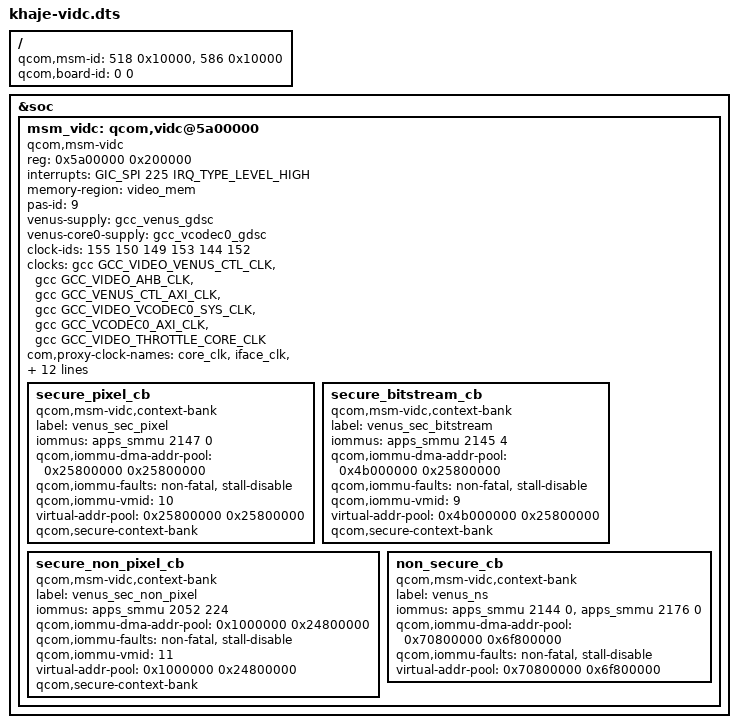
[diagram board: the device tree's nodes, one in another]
// SPDX-License-Identifier: GPL-2.0-only
/*
 * khaje video (msm_vidc) base overlay
 *
 * Reconstructed from the stock Redmi Note 13 4G (sapphire) vendor_boot DTB
 * (HyperOS OS2.0.215.0.VNHEUXM): the Qualcomm "video-devicetree" techpack
 * devicetree is not published, so this overlay was rebuilt from the nodes
 * and properties it contributes to the merged khaje base DTB.  It is applied
 * onto qcom/khaje.dtb with fdtoverlay, as kernel_platform merge_dtbs.py does.
 */

/dts-v1/;
/plugin/;

#include <dt-bindings/clock/qcom,gcc-khaje.h>
#include <dt-bindings/interconnect/qcom,bengal.h>
#include <dt-bindings/interrupt-controller/arm-gic.h>

/ {
	qcom,msm-id = <518 0x10000>, <586 0x10000>;
	qcom,board-id = <0 0>;
};

&soc {
	msm_vidc: qcom,vidc@5a00000 {
		compatible = "qcom,msm-vidc", "qcom,msm-vidc-khaje", "qcom,msm-vidc-ar50lt";
		status = "okay";
		reg = <0x5a00000 0x200000>;
		interrupts = <GIC_SPI 225 IRQ_TYPE_LEVEL_HIGH>;
		memory-region = <&video_mem>;
		pas-id = <9>;
		#address-cells = <1>;
		#size-cells = <1>;
		venus-supply = <&gcc_venus_gdsc>;
		venus-core0-supply = <&gcc_vcodec0_gdsc>;
		clock-names = "core_clk", "iface_clk", "bus_clk", "core0_clk", "core0_bus_clk", "throttle_clk";
		clock-ids = <155 150 149 153 144 152>;
		clocks = <&gcc GCC_VIDEO_VENUS_CTL_CLK &gcc GCC_VIDEO_AHB_CLK
		          &gcc GCC_VENUS_CTL_AXI_CLK &gcc GCC_VIDEO_VCODEC0_SYS_CLK
		          &gcc GCC_VCODEC0_AXI_CLK &gcc GCC_VIDEO_THROTTLE_CORE_CLK>;
		com,proxy-clock-names = "core_clk", "iface_clk", "bus_clk", "core0_clk", "core0_bus_clk", "throttle_clk";
		qcom,clock-configs = <1 0 0 1 0 0>;
		qcom,allowed-clock-rates = <133330000 240000000 300000000 0x16e36000>;
		qcom,reg-presets = <721024 0 3>;
		vidc,firmware-name = "venus";
		interconnect-names = "venus-cnoc", "venus-ddr";
		interconnects = <&bimc MASTER_AMPSS_M0 &config_noc SLAVE_VENUS_CFG
		                 &mmnrt_virt MASTER_VIDEO_P0 &bimc SLAVE_EBI_CH0>;
		qcom,bus-range-kbps = <1000 1000 1000 6500000>;
		secure_pixel_cb {
			compatible = "qcom,msm-vidc,context-bank";
			label = "venus_sec_pixel";
			iommus = <&apps_smmu 2147 0>;
			qcom,iommu-dma-addr-pool = <0x25800000 0x25800000>;
			qcom,iommu-faults = "non-fatal", "stall-disable";
			qcom,iommu-vmid = <10>;
			virtual-addr-pool = <0x25800000 0x25800000>;
			qcom,secure-context-bank;
		};
		secure_bitstream_cb {
			compatible = "qcom,msm-vidc,context-bank";
			label = "venus_sec_bitstream";
			iommus = <&apps_smmu 2145 4>;
			qcom,iommu-dma-addr-pool = <0x4b000000 0x25800000>;
			qcom,iommu-faults = "non-fatal", "stall-disable";
			qcom,iommu-vmid = <9>;
			virtual-addr-pool = <0x4b000000 0x25800000>;
			qcom,secure-context-bank;
		};
		secure_non_pixel_cb {
			compatible = "qcom,msm-vidc,context-bank";
			label = "venus_sec_non_pixel";
			iommus = <&apps_smmu 2052 224>;
			qcom,iommu-dma-addr-pool = <0x1000000 0x24800000>;
			qcom,iommu-faults = "non-fatal", "stall-disable";
			qcom,iommu-vmid = <11>;
			virtual-addr-pool = <0x1000000 0x24800000>;
			qcom,secure-context-bank;
		};
		non_secure_cb {
			compatible = "qcom,msm-vidc,context-bank";
			label = "venus_ns";
			iommus = <&apps_smmu 2144 0 &apps_smmu 2176 0>;
			qcom,iommu-dma-addr-pool = <0x70800000 0x6f800000>;
			qcom,iommu-faults = "non-fatal", "stall-disable";
			virtual-addr-pool = <0x70800000 0x6f800000>;
		};
	};
};
